# R7FA2E1A9 register map
Vendor: Renesas Electronics Corporation; Series: RA2; File version: 0.60.01
CPU: CM23 r1p0, little endian, MPU, no FPU, VTOR, 2 interrupt priority bits, 32 interrupts
Registers are 8-bit, read-write, reset 0x0 unless marked. A register's access mark holds for its fields unless they carry their own. Offsets are from the block's base; [hi:lo] are bit positions; {n}, {i} and the like mark numbered series; 'fields as' and 'values as' point back to an identical list.

## GPT_OPS — Output Phase Switching Controller
Base 0x40078FF0
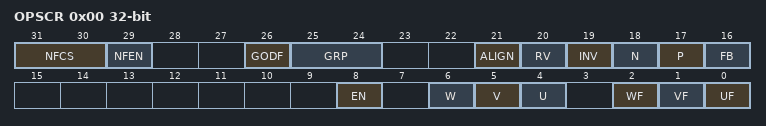
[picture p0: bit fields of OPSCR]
0x00 OPSCR 32-bit — Output Phase Switching Control Register
  [31:30] NFCS — External Input Noise Filter Clock Selection
    0=PCLKD/1; 1=PCLKD/4; 2=PCLKD/16; 3=PCLKD/64
  [29] NFEN — External Input Noise Filter Enable
    0=Do not use a noise filter on the external input; 1=Use a noise filter on the external input
  [26] GODF — Group Output Disable Function
    0=This bit function is ignored; 1=Group disable clears the OPSCR.EN bit
  [25:24] GRP — Output Disabled Source Selection
  [21] ALIGN — Input Phase Alignment
    0=Input phase aligned to PCLKD; 1=Input phase aligned to PWM
  [20] RV — Output Phase Rotation Direction Reversal Control
    0=Positive rotation; 1=Reverse rotation
  [19] INV — Invert-Phase Output Control
    0=Positive logic (active-high) output; 1=Negative logic (active-low) output
  [18] N — Negative-Phase Output (N) Control
    0=Level signal output; 1=PWM signal output (PWM of GPT164)
  [17] P — Positive-Phase Output (P) Control
    0=Level signal output; 1=PWM signal output (PWM of GPT164)
  [16] FB — External Feedback Signal Enable
    0=Select the external input; 1=Select the soft setting (OPSCR.UF, VF, WF)
  [8] EN — Enable-Phase Output Control
    0=Do not output (Hi-Z external pin); 1=Output
  [6] W ro — Input W-Phase Monitor
  [5] V ro — Input V-Phase Monitor
  [4] U ro — Input U-Phase Monitor
  [2] WF
  [1] VF
  [0] UF

## KINT — Key Interrupt Function
Base 0x40080000
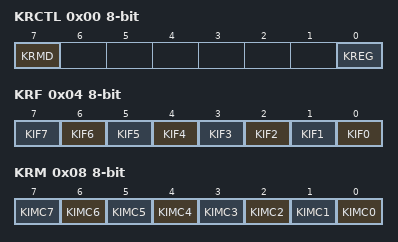
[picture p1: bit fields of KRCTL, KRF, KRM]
0x00 KRCTL — Key Return Control Register
  [7] KRMD — Usage of Key Interrupt Flags (KRF.KIF0 to KRF.KIF7)
    0=Do not use key interrupt flags; 1=Use key interrupt flags
  [0] KREG — Detection Edge Selection (KR00 to KR07 pins)
    0=Falling edge; 1=Rising edge
0x04 KRF — Key Return Flag Register
  [all] fields
    0=No interrupt detected; 1=Interrupt detected
  [n] KIF{n} (n=0..7) — Key Interrupt Flag n
0x08 KRM — Key Return Mode Register
  [all] fields
    0=Do not detect key interrupt signals; 1=Detect key interrupt signals
  [n] KIMC{n} (n=0..7) — Key Interrupt Mode Control n

## ACMPLP — Low-Power Analog Comparator
Base 0x40085E00
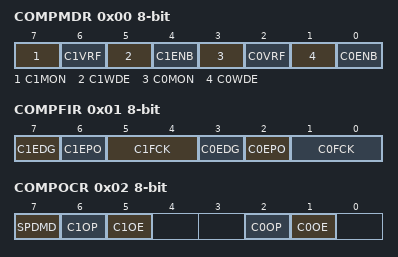
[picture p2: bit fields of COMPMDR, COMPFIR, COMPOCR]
0x00 COMPMDR — ACMPLP Mode Setting Register
  [7] C1MON ro — ACMPLP1 Monitor Flag
  [6] C1VRF — ACMPLP1 Reference Voltage Selection
    0=Select CMPREF1 input as ACMPLP1 reference voltage; 1=Select internal reference voltage (Vref) as ACMPLP1 reference voltage
  [5] C1WDE — ACMPLP1 Window Function Mode Enable
    0=Disable ACMPLP1 window function mode; 1=Enable ACMPLP1 window function mode
  [4] C1ENB — ACMPLP1 Operation Enable
    0=Disable ACMPLP1 operation; 1=Enable ACMPLP1 operation
  [3] C0MON ro — ACMPLP0 Monitor Flag
  [2] C0VRF — ACMPLP0 Reference Voltage Selection
    0=Select CMPREF0 input as ACMPLP0 reference voltage; 1=Select internal reference voltage (Vref) as ACMPLP0 reference voltage
  [1] C0WDE — ACMPLP0 Window Function Mode Enable
    0=Disable window function for ACMPLP0; 1=Enable window function for ACMPLP0
  [0] C0ENB — ACMPLP0 Operation Enable
    0=Disable comparator channel ACMPLP0; 1=Enable comparator channel ACMPLP0
0x01 COMPFIR — ACMPLP Filter Control Register
  [7] C1EDG — ACMPLP1 Edge Detection Selection
    0=Interrupt and ELC event request by one-edge detection; 1=Interrupt and ELC event request by both-edge detection
  [6] C1EPO — ACMPLP1 Edge Polarity Switching
    0=Interrupt and ELC event request on rising edge; 1=Interrupt and ELC event request on falling edge
  [5:4] C1FCK — ACMPLP1 Filter Select
    0=No Sampling (bypass); 1=Sampling at PCLKB; 2=Sampling at PCLKB/8; 3=Sampling at PCLKB/32
  [3] C0EDG — ACMPLP0 Edge Detection Selection
    values as C1EDG
  [2] C0EPO — ACMPLP0 Edge Polarity Switching
    values as C1EPO
  [1:0] C0FCK — ACMPLP0 Filter Select
    values as C1FCK
0x02 COMPOCR — ACMPLP Output Control Register
  [7] SPDMD — ACMPLP0/ACMPLP1 Speed Selection
    0=Low-speed mode; 1=High-speed mode
  [6] C1OP — ACMPLP1 VCOUT Output Polarity Selection
    0=Non-inverted; 1=Inverted
  [5] C1OE — ACMPLP1 VCOUT Pin Output Enable
    0=Disabled; 1=Enabled
  [2] C0OP — ACMPLP0 VCOUT Output Polarity Selection
    0=Non-inverted; 1=Inverted
  [1] C0OE — ACMPLP0 VCOUT Pin Output Enable
    0=Disabled; 1=Enabled
